AUTOSAR XML (schema 4-0-3)
standard types defined: uint8, Boolean, UInt16, UInt32, UInt8
package /AUTOSAR_Platform/DataConstrs
  range DC_Boolean: raw 0..1
  range DC_UInt16: raw 0..65535
  range DC_UInt8: raw 0..255
package /PATAC/Facility/DataTypes/Implementation
  compu method COMPU_Boolean: 0=FALSE, 1=TRUE
  unit NoUnit: factor-si-to-unit=1, offset-si-to-unit=0
package /PATAC/MSM/ComponentTypes
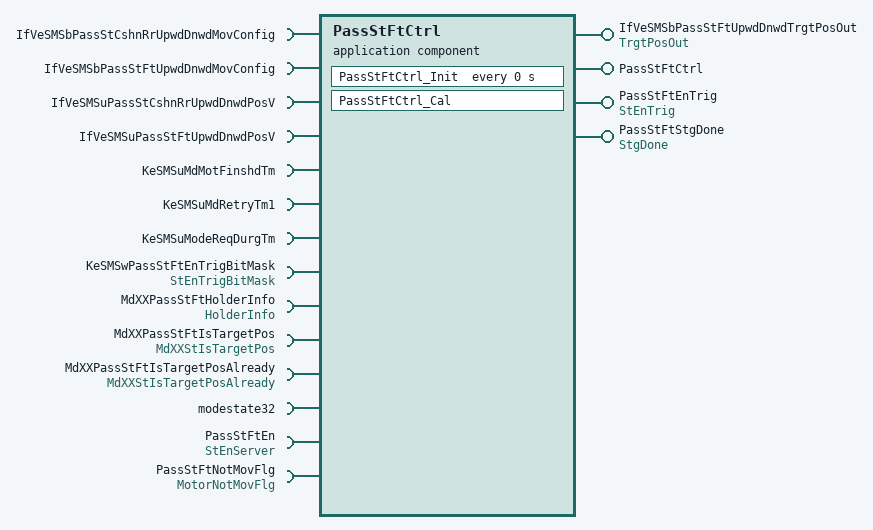
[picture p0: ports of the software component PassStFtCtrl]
  application sw component type PassStFtCtrl
    4 x provide port:
      IfVeSMSbPassStFtUpwdDnwdTrgtPosOut: nonqueued-sender-com-spec{data-element=TrgtPosOut/Val, init-value=0}, provided-interface=TrgtPosOut
      PassStFtCtrl: server-com-spec{operation=Cal, queue-length=1}, provided-interface=PassStFtCtrl
      PassStFtEnTrig: nonqueued-sender-com-spec{data-element=StEnTrig/Val, init-value=0}, provided-interface=StEnTrig
      PassStFtStgDone: nonqueued-sender-com-spec{data-element=StgDone/Val, init-value=0}, provided-interface=StgDone
    14 x require port:
      IfVeSMSbPassStCshnRrUpwdDnwdMovConfig: nonqueued-receiver-com-spec{data-element=IfVeSMSbPassStCshnRrUpwdDnwdMovConfig/Val, filter=data-filter-type=ALWAYS}, required-interface=IfVeSMSbPassStCshnRrUpwdDnwdMovConfig
      IfVeSMSbPassStFtUpwdDnwdMovConfig: nonqueued-receiver-com-spec{data-element=IfVeSMSbPassStFtUpwdDnwdMovConfig/Val, filter=data-filter-type=ALWAYS, init-value=0}, required-interface=IfVeSMSbPassStFtUpwdDnwdMovConfig
      IfVeSMSuPassStCshnRrUpwdDnwdPosV: nonqueued-receiver-com-spec{data-element=IfVeSMSuPassStCshnRrUpwdDnwdPosV/Val, filter=data-filter-type=ALWAYS}, required-interface=IfVeSMSuPassStCshnRrUpwdDnwdPosV
      IfVeSMSuPassStFtUpwdDnwdPosV: nonqueued-receiver-com-spec{data-element=IfVeSMSuPassStFtUpwdDnwdPosV/Val, filter=data-filter-type=ALWAYS, init-value=0}, required-interface=IfVeSMSuPassStFtUpwdDnwdPosV
      KeSMSuMdMotFinshdTm: parameter-require-com-spec{init-value=0, parameter=KeSMSuMdMotFinshdTm/Val}, required-interface=KeSMSuMdMotFinshdTm
      KeSMSuMdRetryTm1: parameter-require-com-spec{init-value=0, parameter=KeSMSuMdRetryTm1/Val}, required-interface=KeSMSuMdRetryTm1
      KeSMSuModeReqDurgTm: parameter-require-com-spec{init-value=0, parameter=KeSMSuModeReqDurgTm/Val}, required-interface=KeSMSuModeReqDurgTm
      KeSMSwPassStFtEnTrigBitMask: parameter-require-com-spec{init-value=6153, parameter=StEnTrigBitMask/Val}, required-interface=StEnTrigBitMask
      MdXXPassStFtHolderInfo: nonqueued-receiver-com-spec{data-element=HolderInfo/Val, filter=data-filter-type=ALWAYS, init-value=0}, required-interface=HolderInfo
      MdXXPassStFtIsTargetPos: nonqueued-receiver-com-spec{data-element=MdXXStIsTargetPos/Val, filter=data-filter-type=ALWAYS, init-value=0}, required-interface=MdXXStIsTargetPos
      MdXXPassStFtIsTargetPosAlready: nonqueued-receiver-com-spec{data-element=MdXXStIsTargetPosAlready/Val, filter=data-filter-type=ALWAYS, init-value=0}, required-interface=MdXXStIsTargetPosAlready
      modestate32: nonqueued-receiver-com-spec{data-element=modestate32/Val, filter=data-filter-type=ALWAYS, init-value=0}, required-interface=modestate32
      PassStFtEn: required-com-specs=[Clear, Get, Set], required-interface=StEnServer
      PassStFtNotMovFlg: nonqueued-receiver-com-spec{data-element=MotorNotMovFlg/Val, filter=data-filter-type=ALWAYS, init-value=0}, required-interface=MotorNotMovFlg
    behavior PassStFtCtrl_InternalBehavior
      operation invoked event OIT_PassStFtCtrl_Cal_PassStFtCtrl_Cal: start-on-event=PassStFtCtrl_Cal, operation=PassStFtCtrl.Cal
      timing event PassStFtCtrl_InitEvent: start-on-event=PassStFtCtrl_Init, period=0
      runnable PassStFtCtrl_Cal
        data-receive-point-by-arguments:
          9 x access:
            REC_IfVeSMSbPassStCshnRrUpwdDnwdMovConfig_Val: accessed-variable=IfVeSMSbPassStCshnRrUpwdDnwdMovConfig.Val
            REC_IfVeSMSbPassStFtUpwdDnwdMovConfig_Val: accessed-variable=IfVeSMSbPassStFtUpwdDnwdMovConfig.Val
            REC_IfVeSMSuPassStCshnRrUpwdDnwdPosV_Val: accessed-variable=IfVeSMSuPassStCshnRrUpwdDnwdPosV.Val
            REC_IfVeSMSuPassStFtUpwdDnwdPosV_Val: accessed-variable=IfVeSMSuPassStFtUpwdDnwdPosV.Val
            REC_MdXXPassStFtHolderInfo_Val: accessed-variable=MdXXPassStFtHolderInfo.Val
            REC_MdXXPassStFtIsTargetPos_Val: accessed-variable=MdXXPassStFtIsTargetPos.Val
            REC_MdXXPassStFtIsTargetPosAlready_Val: accessed-variable=MdXXPassStFtIsTargetPosAlready.Val
            REC_modestate32_Val: accessed-variable=modestate32.Val
            REC_PassStFtNotMovFlg_Val: accessed-variable=PassStFtNotMovFlg.Val
        data-send-points:
          access SEND_IfVeSMSbPassStFtUpwdDnwdTrgtPosOut_Val: accessed-variable=IfVeSMSbPassStFtUpwdDnwdTrgtPosOut.Val
          access SEND_PassStFtEnTrig_Val: accessed-variable=PassStFtEnTrig.Val
          access SEND_PassStFtStgDone_Val: accessed-variable=PassStFtStgDone.Val
        4 x parameter access:
          PA_KeSMSuMdMotFinshdTm_Val: accessed-parameter=KeSMSuMdMotFinshdTm.Val
          PA_KeSMSuMdRetryTm1_Val: accessed-parameter=KeSMSuMdRetryTm1.Val
          PA_KeSMSuModeReqDurgTm_Val: accessed-parameter=KeSMSuModeReqDurgTm.Val
          PA_KeSMSwPassStFtEnTrigBitMask_Val: accessed-parameter=KeSMSwPassStFtEnTrigBitMask.Val
        sync call SC_PassStFtEn_Get: operation=PassStFtEn.Get, timeout=0
      runnable PassStFtCtrl_Init
        4 x parameter access:
          PA_KeSMSuMdMotFinshdTm_Val: accessed-parameter=KeSMSuMdMotFinshdTm.Val
          PA_KeSMSuMdRetryTm1_Val: accessed-parameter=KeSMSuMdRetryTm1.Val
          PA_KeSMSuModeReqDurgTm_Val: accessed-parameter=KeSMSuModeReqDurgTm.Val
          PA_KeSMSwPassStFtEnTrigBitMask_Val: accessed-parameter=KeSMSwPassStFtEnTrigBitMask.Val
  swc implementation PassStFtCtrl_Implementation: behavior=PassStFtCtrl_InternalBehavior
    code-descriptors:
      code Default: artifact-descriptors=autosar-engineering-object={short-label=Default, category=SWSRC}
package /PATAC/MSM/ModeAdjust/CalPortInterface
  parameter interface KeSMSuMdMotFinshdTm
    parameter data prototype Val: sw-calibration-access=READ-WRITE, type=UInt16
  parameter interface KeSMSuModeReqDurgTm
    parameter data prototype Val: sw-calibration-access=READ-WRITE, type=UInt16
  parameter interface StEnTrigBitMask
    parameter data prototype Val: sw-calibration-access=READ-WRITE, type=UInt32
package /PATAC/MSM/ModeAdjust/Interfaces
  sender receiver interface IfVeSMSuPassStCshnRrUpwdDnwdPosV: invalidation-policy{data-element=IfVeSMSuPassStCshnRrUpwdDnwdPosV/Val, handle-invalid=DONT-INVALIDATE}
    data Val: type=Boolean
  sender receiver interface IfVeSMSuPassStFtUpwdDnwdPosV: invalidation-policy{data-element=IfVeSMSuPassStFtUpwdDnwdPosV/Val, handle-invalid=DONT-INVALIDATE}
    data Val: type=Boolean
package /PATAC/MSM/ModeAdjust/PortInterface
  client server interface PassStFtCtrl
    operation Cal
  client server interface StEnServer
    operation Clear
      arg data: type=UInt8, direction=IN, server-argument-impl-policy=USE-ARGUMENT-TYPE
    operation Get
      arg data: type=UInt32, direction=OUT, server-argument-impl-policy=USE-ARGUMENT-TYPE
    operation Set
      arg data: type=UInt8, direction=IN, server-argument-impl-policy=USE-ARGUMENT-TYPE
  8 x sender receiver interface:
    HolderInfo: invalidation-policy{data-element=HolderInfo/Val, handle-invalid=DONT-INVALIDATE}
      data Val: type=UInt32
    MdXXStIsTargetPos: invalidation-policy{data-element=MdXXStIsTargetPos/Val, handle-invalid=DONT-INVALIDATE}
      data Val: type=UInt32
    MdXXStIsTargetPosAlready: invalidation-policy{data-element=MdXXStIsTargetPosAlready/Val, handle-invalid=DONT-INVALIDATE}
      data Val: type=UInt32
    modestate32: invalidation-policy{data-element=modestate32/Val, handle-invalid=DONT-INVALIDATE}
      data Val: type=UInt32
    MotorNotMovFlg: invalidation-policy{data-element=MotorNotMovFlg/Val, handle-invalid=DONT-INVALIDATE}
      data Val: type=Boolean
    StEnTrig: invalidation-policy{data-element=StEnTrig/Val, handle-invalid=DONT-INVALIDATE}
      data Val: type=Boolean
    StgDone: invalidation-policy{data-element=StgDone/Val, handle-invalid=DONT-INVALIDATE}
      data Val: type=Boolean
    TrgtPosOut: invalidation-policy{data-element=TrgtPosOut/Val, handle-invalid=DONT-INVALIDATE}
      data Val: type=Boolean
package /PATAC/MSM/PortInterfaces
  parameter interface KeSMSuMdRetryTm1
    parameter data prototype Val: sw-calibration-access=READ-WRITE, type=UInt8
  sender receiver interface IfVeSMSbPassStCshnRrUpwdDnwdMovConfig: invalidation-policy{data-element=IfVeSMSbPassStCshnRrUpwdDnwdMovConfig/Val, handle-invalid=DONT-INVALIDATE}
    data Val: type=Boolean
  sender receiver interface IfVeSMSbPassStFtUpwdDnwdMovConfig: invalidation-policy{data-element=IfVeSMSbPassStFtUpwdDnwdMovConfig/Val, handle-invalid=DONT-INVALIDATE}
    data Val: type=Boolean
